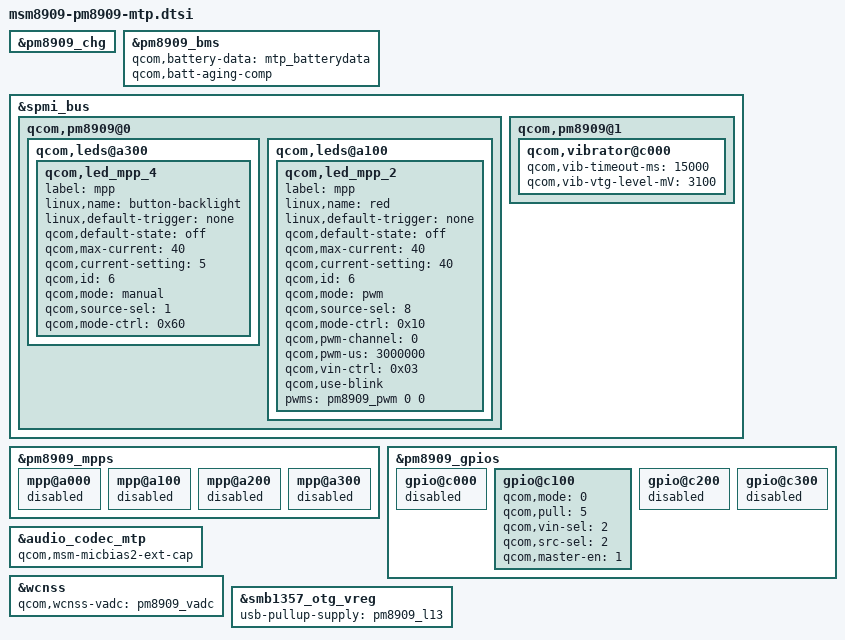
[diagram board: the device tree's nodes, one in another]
/*
 * Copyright (c) 2014-2015, The Linux Foundation. All rights reserved.
 *
 * This program is free software; you can redistribute it and/or modify
 * it under the terms of the GNU General Public License version 2 and
 * only version 2 as published by the Free Software Foundation.
 *
 * This program is distributed in the hope that it will be useful,
 * but WITHOUT ANY WARRANTY; without even the implied warranty of
 * MERCHANTABILITY or FITNESS FOR A PARTICULAR PURPOSE.  See the
 * GNU General Public License for more details.
 */

&pm8909_chg {
	status = "ok";
	//[Feature]-Add-BEGIN by TCTSZ. enable pm8909 charging for charging porting junfeng.zhou.sz@tcl.com, 2015/6/19, for PR369037
	//qcom,charging-disabled;
	//[Feature]-Add-END by TCTSZ. junfeng.zhou.sz@tcl.com, 2015/6/19, for PR369037
};

&pm8909_bms {
	status = "ok";
	qcom,battery-data = <&mtp_batterydata>;
	qcom,batt-aging-comp;
};

&spmi_bus {
	qcom,pm8909@0 {
		qcom,leds@a300 {
			status = "okay";
			qcom,led_mpp_4 {
				label = "mpp";
				linux,name = "button-backlight";
				linux,default-trigger = "none";
				qcom,default-state = "off";
				qcom,max-current = <40>;
				qcom,current-setting = <5>;
				qcom,id = <6>;
				qcom,mode = "manual";
				qcom,source-sel = <1>;
				qcom,mode-ctrl = <0x60>;
			};
		};
	//[Feature]-Add-BEGIN by TCTSZ. add a leds device for leds driver porting junfeng.zhou.sz@tcl.com, 2015/6/19, for PR367664
       qcom,leds@a100 {   //mpp2
            status = "okay";
			qcom,led_mpp_2 {
				label = "mpp";
				linux,name = "red";
				linux,default-trigger = "none";
				qcom,default-state = "off";
				qcom,max-current = <40>;
				qcom,current-setting = <40>;
				qcom,id = <6>;
				qcom,mode = "pwm";
				qcom,source-sel = <8>;
				qcom,mode-ctrl = <0x10>;
				qcom,pwm-channel = <0>;
				qcom,pwm-us = <3000000>;
				qcom,vin-ctrl = <0x03>;
				qcom,use-blink;
				pwms = <&pm8909_pwm 0 0>;
			};
		};
	//[Feature]-Add-END by TCTSZ. junfeng.zhou.sz@tcl.com, 2015/6/19, for PR367664
	};

	qcom,pm8909@1 {
		qcom,vibrator@c000 {
			status = "okay";
			qcom,vib-timeout-ms = <15000>;
			qcom,vib-vtg-level-mV = <3100>;
		};
	};
};

&pm8909_mpps {
	mpp@a000 { /* MPP 1 */
		/* VDD_PX */
		status = "disabled";
	};

	mpp@a100 { /* MPP 2 */
	//[Del]-Add-BEGIN by TCTSZ. Del qcom mpp2 configs for leds driver porting junfeng.zhou.sz@tcl.com, 2015/6/19, for PR367664
		/* Backlight PWM */
		//qcom,mode = <1>;		/* Digital output */
		//qcom,invert = <0>;		/* Disable invert */
		//qcom,src-sel = <4>;		/* DTEST1 */
		//qcom,vin-sel = <0>;		/* VPH_PWR */
		//qcom,master-en = <1>;		/* Enable MPP */
        /* CHG LED */
		status = "disabled";
	//[Feature]-Add-END by TCTSZ. junfeng.zhou.sz@tcl.com, 2015/6/19, for PR367664
	};

	mpp@a200 { /* MPP 3 */
		/* VREF DAC */
		status = "disabled";
	};

	mpp@a300 { /* MPP 4 */
		/* HR LED */
		status = "disabled";
	};
};

&pm8909_gpios {
	gpio@c000 { /* GPIO 1 */
		/* Battery UICC Alarm */
		status = "disabled";
	};

	gpio@c100 { /* GPIO 2 */
		/* NFC_CLK_REQ */
		qcom,mode = <0>; /* QPNP_PIN_MODE_DIG_IN */
		qcom,pull = <5>; /* QPNP_PIN_PULL_NO */
		qcom,vin-sel = <2>; /* QPNP_PIN_VIN2 */
		qcom,src-sel = <2>; /* QPNP_PIN_SEL_FUNC_1 */
		qcom,master-en = <1>;
	};

	gpio@c200 { /* GPIO 3 */
		/* External regulator control for WTR */
		status = "disabled";
	};

	gpio@c300 { /* GPIO 4 */
		/* External regulator control for APC */
		status = "disabled";
	};
};

&audio_codec_mtp {
	qcom,msm-micbias2-ext-cap;
};

//ting.kang move for main mic and sub mic can't work start
/*&spk_vreg {
	status = "okay";
};

&pm8909_conga_dig {
	cdc-vdd-spkdrv-supply = <&spk_vreg>;
	qcom,cdc-vdd-spkdrv-voltage = <5000000 5000000>;
	qcom,cdc-vdd-spkdrv-current = <20000>;
	qcom,cdc-on-demand-supplies = "cdc-vdd-mic-bias",
				      "cdc-vdd-spkdrv";
};*/
//ting.kang move for main mic and sub mic can't work end

&wcnss {
	qcom,wcnss-vadc = <&pm8909_vadc>;
};

&smb1357_otg_vreg {
	usb-pullup-supply = <&pm8909_l13>;
};
